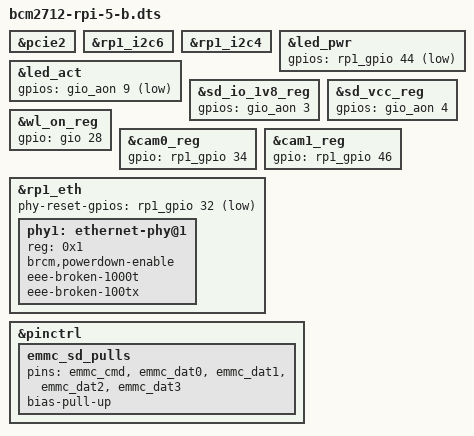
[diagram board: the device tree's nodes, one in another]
// SPDX-License-Identifier: (GPL-2.0 OR MIT)
/*
 * bcm2712-rpi-5-b-ovl-rp1.dts is the overlay-ready DT which will make
 * the RP1 driver to load the RP1 dtb overlay at runtime, while
 * bcm2712-rpi-5-b.dts (this file) is the fully defined one (i.e. it
 * already contains RP1 node, so no overlay is loaded nor needed).
 * This file is not intended to be modified, nodes should be added
 * to the included bcm2712-rpi-5-b-ovl-rp1.dts.
 */

/dts-v1/;

#include "bcm2712-rpi-5-b-ovl-rp1.dts"

&pcie2 {
	#include "rp1-nexus.dtsi"
};


/*
 * Our downstream modifications assume that RP1 is present, therefore add them
 * here instead of bcm2712-rpi-5-b-ovl-rp1.dts
 */
// Downstream BCM2712 SoC changes
#include "bcm2712-ds.dtsi"

i2c_csi_dsi0: &rp1_i2c6 { };
i2c_csi_dsi1: &rp1_i2c4 { };

i2c_csi_dsi: &i2c_csi_dsi1 { }; // An alias for compatibility

// Generic Pi downstream changes
#include "bcm2712-rpi-ds.dtsi"

&led_pwr {
	gpios = <&rp1_gpio 44 GPIO_ACTIVE_LOW>;
};

&led_act {
	gpios = <&gio_aon 9 GPIO_ACTIVE_LOW>;
};

&sd_io_1v8_reg {
	gpios = <&gio_aon 3 GPIO_ACTIVE_HIGH>;
};

&sd_vcc_reg {
	gpios = <&gio_aon 4 GPIO_ACTIVE_HIGH>;
};

&wl_on_reg {
	gpio = <&gio 28 GPIO_ACTIVE_HIGH>;
};

&cam0_reg {
	gpio = <&rp1_gpio 34 0>;  // CD0_IO0_MICCLK, to MIPI 0 connector
};

&cam1_reg {
	gpio = <&rp1_gpio 46 0>;  // CD1_IO0_MICCLK, to MIPI 1 connector
};

&rp1_eth {
	phy-reset-gpios = <&rp1_gpio 32 GPIO_ACTIVE_LOW>;

	phy1: ethernet-phy@1 {
		reg = <0x1>;
		brcm,powerdown-enable;
		eee-broken-1000t;
		eee-broken-100tx;
	};
};

&pinctrl {
	emmc_sd_pulls: emmc_sd_pulls {
		pins = "emmc_cmd", "emmc_dat0", "emmc_dat1", "emmc_dat2", "emmc_dat3";
		bias-pull-up;
	};
};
